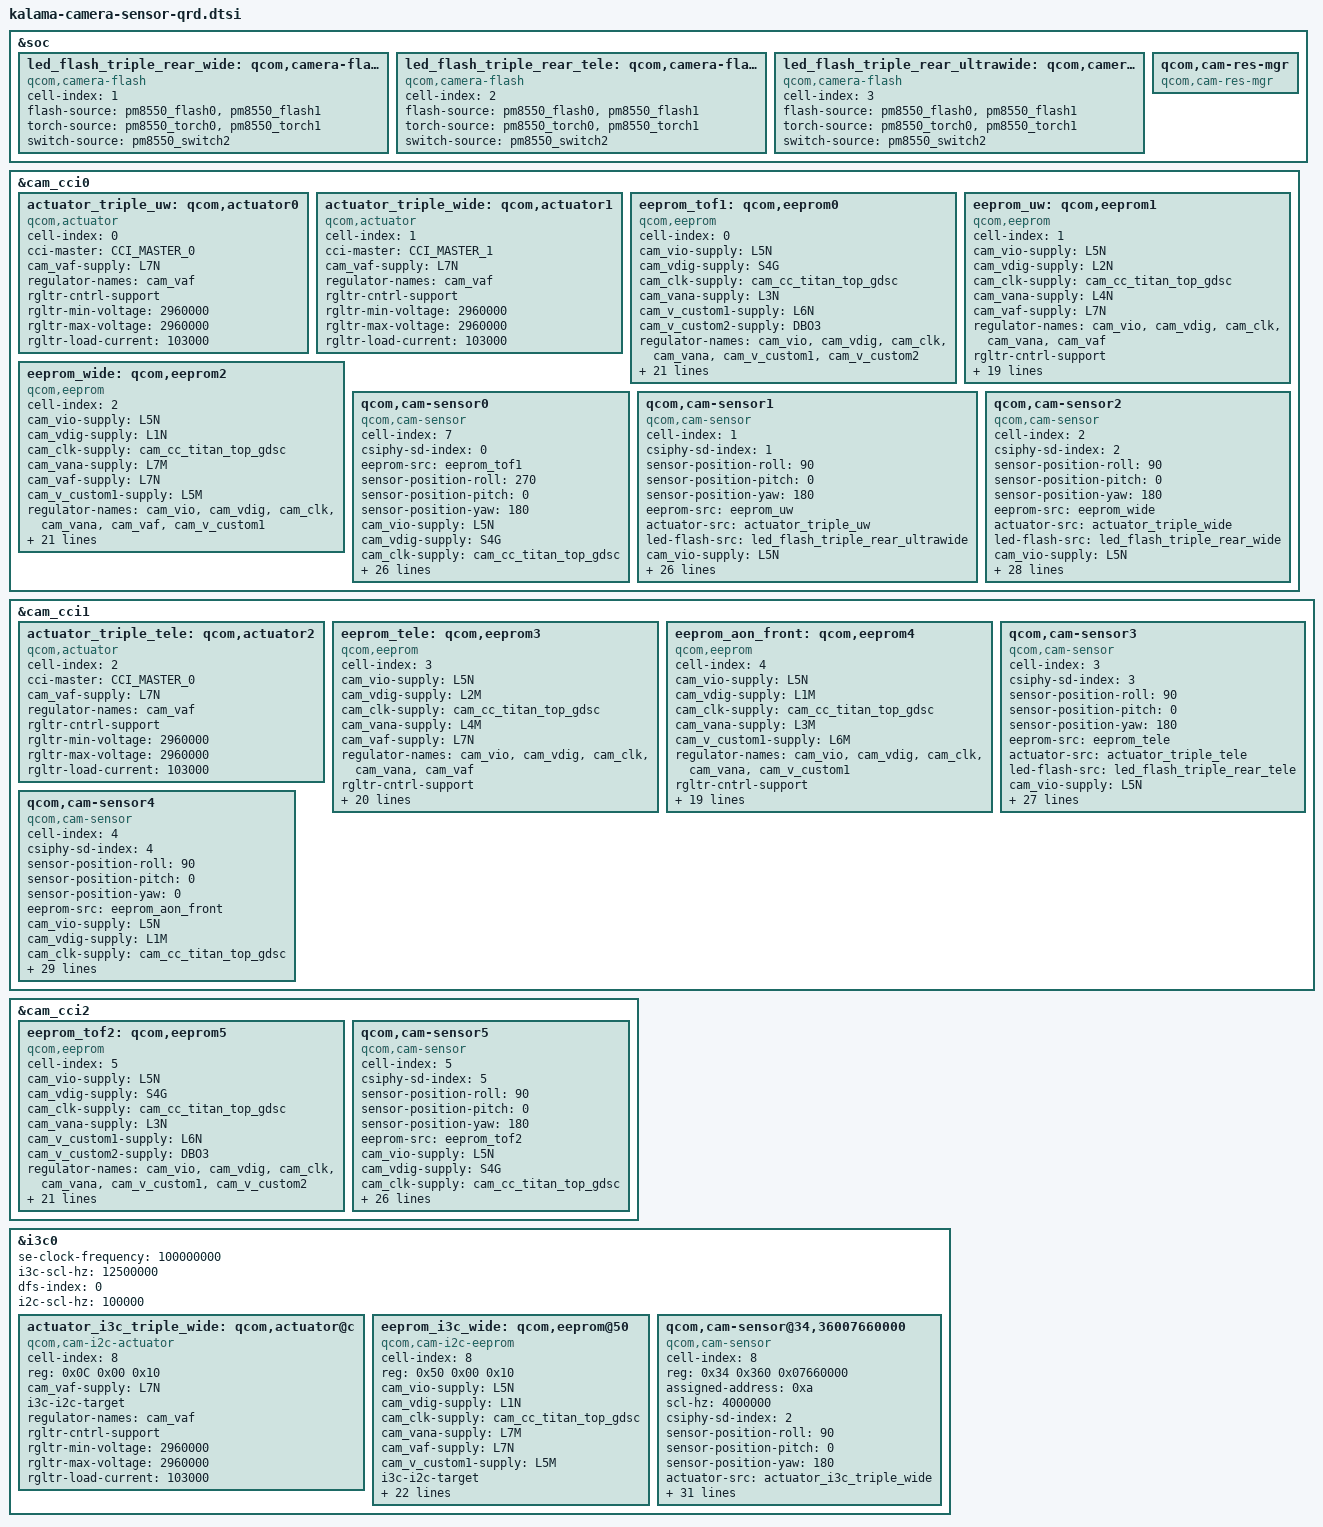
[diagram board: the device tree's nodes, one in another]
#include <dt-bindings/msm-camera.h>

&soc {
	led_flash_triple_rear_wide: qcom,camera-flash1 {
		cell-index = <1>;
		compatible = "qcom,camera-flash";
		flash-source = <&pm8550_flash0 &pm8550_flash1>;
		torch-source = <&pm8550_torch0 &pm8550_torch1>;
		switch-source = <&pm8550_switch2>;
		status = "ok";
	};

	led_flash_triple_rear_tele: qcom,camera-flash2 {
		cell-index = <2>;
		compatible = "qcom,camera-flash";
		flash-source = <&pm8550_flash0 &pm8550_flash1>;
		torch-source = <&pm8550_torch0 &pm8550_torch1>;
		switch-source = <&pm8550_switch2>;
		status = "ok";
	};

	led_flash_triple_rear_ultrawide: qcom,camera-flash3 {
		cell-index = <3>;
		compatible = "qcom,camera-flash";
		flash-source = <&pm8550_flash0 &pm8550_flash1>;
		torch-source = <&pm8550_torch0 &pm8550_torch1>;
		switch-source = <&pm8550_switch2>;
		status = "ok";
	};

	qcom,cam-res-mgr {
		compatible = "qcom,cam-res-mgr";
		status = "ok";
	};
};

&cam_cci0 {
	actuator_triple_uw: qcom,actuator0 {
		cell-index = <0>;
		compatible = "qcom,actuator";
		cci-master = <CCI_MASTER_0>;
		cam_vaf-supply = <&L7N>;
		regulator-names = "cam_vaf";
		rgltr-cntrl-support;
		rgltr-min-voltage = <2960000>;
		rgltr-max-voltage = <2960000>;
		rgltr-load-current = <103000>;
		status = "ok";
	};

	actuator_triple_wide: qcom,actuator1 {
		cell-index = <1>;
		compatible = "qcom,actuator";
		cci-master = <CCI_MASTER_1>;
		cam_vaf-supply = <&L7N>;
		regulator-names = "cam_vaf";
		rgltr-cntrl-support;
		rgltr-min-voltage = <2960000>;
		rgltr-max-voltage = <2960000>;
		rgltr-load-current = <103000>;
		status = "ok";
	};

	eeprom_tof1: qcom,eeprom0 {
		cell-index = <0>;
		compatible = "qcom,eeprom";
		cam_vio-supply = <&L5N>;
		cam_vdig-supply = <&S4G>;
		cam_clk-supply = <&cam_cc_titan_top_gdsc>;
		cam_vana-supply = <&L3N>;
		cam_v_custom1-supply = <&L6N>;
		cam_v_custom2-supply = <&DBO3>;
		regulator-names = "cam_vio", "cam_vdig",
			"cam_clk", "cam_vana", "cam_v_custom1", "cam_v_custom2";
		rgltr-cntrl-support;
		rgltr-min-voltage = <1800000 1200000 0 2800000 3304000 3600000>;
		rgltr-max-voltage = <1800000 1352000 0 2800000 3304000 3600000>;
		rgltr-load-current = <155000 680000 0 50000 30000 2500000>;
		gpio-no-mux = <0>;
		pinctrl-names = "cam_default", "cam_suspend";
		pinctrl-0 = <&cam_sensor_mclk0_active
			&cam_sensor_active_rst0>;
		pinctrl-1 = <&cam_sensor_mclk0_suspend
			&cam_sensor_suspend_rst0>;
		gpios = <&tlmm 100 0>,
			<&tlmm 116 0>;
		gpio-reset = <1>;
		gpio-req-tbl-num = <0 1>;
		gpio-req-tbl-flags = <1 0>;
		gpio-req-tbl-label = "CAMIF_MCLK0",
					"CAM_RESET0";
		cci-master = <CCI_MASTER_0>;
		clocks = <&camcc CAM_CC_MCLK0_CLK>;
		clock-names = "cam_clk";
		clock-cntl-level = "nominal";
		clock-rates = <24000000>;
		status = "ok";
	};

	eeprom_uw: qcom,eeprom1 {
		cell-index = <1>;
		compatible = "qcom,eeprom";
		cam_vio-supply = <&L5N>;
		cam_vdig-supply = <&L2N>;
		cam_clk-supply = <&cam_cc_titan_top_gdsc>;
		cam_vana-supply = <&L4N>;
		cam_vaf-supply = <&L7N>;
		regulator-names = "cam_vio", "cam_vdig", "cam_clk",
			"cam_vana","cam_vaf";
		rgltr-cntrl-support;
		rgltr-min-voltage = <1800000 1104000 0 2800000  2960000>;
		rgltr-max-voltage = <1800000 1104000 0 2800000  2960000>;
		rgltr-load-current = <3000 644000 0 95000  103000>;
		gpio-no-mux = <0>;
		pinctrl-names = "cam_default", "cam_suspend";
		pinctrl-0 = <&cam_sensor_mclk1_active
				 &cam_sensor_active_rst1>;
		pinctrl-1 = <&cam_sensor_mclk1_suspend
				 &cam_sensor_suspend_rst1>;
		gpios = <&tlmm 101 0>,
			<&tlmm 117 0>;
		gpio-reset = <1>;
		gpio-req-tbl-num = <0 1>;
		gpio-req-tbl-flags = <1 0>;
		gpio-req-tbl-label = "CAMIF_MCLK1",
					"CAM_RESET1";
		cci-master = <CCI_MASTER_0>;
		clocks = <&camcc CAM_CC_MCLK1_CLK>;
		clock-names = "cam_clk";
		clock-cntl-level = "nominal";
		clock-rates = <24000000>;
		status = "ok";
	};

	eeprom_wide: qcom,eeprom2 {
		cell-index = <2>;
		compatible = "qcom,eeprom";
		cam_vio-supply = <&L5N>;
		cam_vdig-supply = <&L1N>;
		cam_clk-supply = <&cam_cc_titan_top_gdsc>;
		cam_vana-supply = <&L7M>;
		cam_vaf-supply = <&L7N>;
		cam_v_custom1-supply = <&L5M>;
		regulator-names = "cam_vio", "cam_vdig", "cam_clk", "cam_vana",
			"cam_vaf", "cam_v_custom1";
		rgltr-cntrl-support;
		rgltr-min-voltage = <1800000 1104000 0 2800000 2960000 1800000>;
		rgltr-max-voltage = <1800000 1104000 0 2800000 2960000 1800000>;
		rgltr-load-current = <3500 913200 0 91300 103000 63100>;
		gpio-no-mux = <0>;
		pinctrl-names = "cam_default", "cam_suspend";
		pinctrl-0 = <&cam_sensor_mclk2_active
				&cam_sensor_active_rst2>;
		pinctrl-1 = <&cam_sensor_mclk2_suspend
				&cam_sensor_suspend_rst2>;
		gpios = <&tlmm 102 0>,
			<&tlmm 118 0>;
		gpio-reset = <1>;
		gpio-req-tbl-num = <0 1>;
		gpio-req-tbl-flags = <1 0>;
		gpio-req-tbl-label = "CAMIF_MCLK2",
					"CAM_RESET2";
		cci-master = <CCI_MASTER_1>;
		clocks = <&camcc CAM_CC_MCLK2_CLK>;
		clock-names = "cam_clk";
		clock-cntl-level = "nominal";
		clock-rates = <24000000>;
		status = "ok";
	};

	qcom,cam-sensor0 {
		cell-index = <7>;
		compatible = "qcom,cam-sensor";
		csiphy-sd-index = <0>;
		eeprom-src = <&eeprom_tof1>;
		sensor-position-roll = <270>;
		sensor-position-pitch = <0>;
		sensor-position-yaw = <180>;
		cam_vio-supply = <&L5N>;
		cam_vdig-supply = <&S4G>;
		cam_clk-supply = <&cam_cc_titan_top_gdsc>;
		cam_vana-supply = <&L3N>;
		cam_v_custom1-supply = <&L6N>;
		cam_v_custom2-supply = <&DBO3>;
		regulator-names = "cam_vio", "cam_vdig",
			"cam_clk", "cam_vana", "cam_v_custom1", "cam_v_custom2";
		rgltr-cntrl-support;
		rgltr-min-voltage = <1800000 1200000 0 2800000 3304000 3600000>;
		rgltr-max-voltage = <1800000 1352000 0 2800000 3304000 3600000>;
		rgltr-load-current = <155000 680000 0 50000 30000 2500000>;
		gpio-no-mux = <0>;
		pinctrl-names = "cam_default", "cam_suspend";
		pinctrl-0 = <&cam_sensor_mclk0_active
			&cam_sensor_active_rst0>;
		pinctrl-1 = <&cam_sensor_mclk0_suspend
			&cam_sensor_suspend_rst0>;
		gpios = <&tlmm 100 0>,
			<&tlmm 116 0>;
		gpio-reset = <1>;
		gpio-req-tbl-num = <0 1>;
		gpio-req-tbl-flags = <1 0>;
		gpio-req-tbl-label = "CAMIF_MCLK0",
					"CAM_RESET0";
		cci-master = <0>;
		clocks = <&camcc CAM_CC_MCLK0_CLK>;
		clock-names = "cam_clk";
		clock-cntl-level = "nominal";
		clock-rates = <24000000>;
		status = "ok";
	};

	qcom,cam-sensor1 {
		cell-index = <1>;
		compatible = "qcom,cam-sensor";
		csiphy-sd-index = <1>;
		sensor-position-roll = <90>;
		sensor-position-pitch = <0>;
		sensor-position-yaw = <180>;
		eeprom-src = <&eeprom_uw>;
		actuator-src = <&actuator_triple_uw>;
		led-flash-src = <&led_flash_triple_rear_ultrawide>;
		cam_vio-supply = <&L5N>;
		cam_vdig-supply = <&L2N>;
		cam_clk-supply = <&cam_cc_titan_top_gdsc>;
		cam_vana-supply = <&L4N>;
		cam_vaf-supply = <&L7N>;
		regulator-names = "cam_vio", "cam_vdig", "cam_clk",
			"cam_vana","cam_vaf";
		rgltr-cntrl-support;
		rgltr-min-voltage = <1800000 1104000 0 2800000  2960000>;
		rgltr-max-voltage = <1800000 1104000 0 2800000  2960000>;
		rgltr-load-current = <3000 644000 0 95000  103000>;
		gpio-no-mux = <0>;
		pinctrl-names = "cam_default", "cam_suspend";
		pinctrl-0 = <&cam_sensor_mclk1_active
				 &cam_sensor_active_rst1>;
		pinctrl-1 = <&cam_sensor_mclk1_suspend
				 &cam_sensor_suspend_rst1>;
		gpios = <&tlmm 101 0>,
			<&tlmm 117 0>;
		gpio-reset = <1>;
		gpio-req-tbl-num = <0 1>;
		gpio-req-tbl-flags = <1 0>;
		gpio-req-tbl-label = "CAMIF_MCLK1",
					"CAM_RESET1";
		cci-master = <CCI_MASTER_0>;
		clocks = <&camcc CAM_CC_MCLK1_CLK>;
		clock-names = "cam_clk";
		clock-cntl-level = "nominal";
		clock-rates = <24000000>;
		status = "ok";
	};

	qcom,cam-sensor2 {
		cell-index = <2>;
		compatible = "qcom,cam-sensor";
		csiphy-sd-index = <2>;
		sensor-position-roll = <90>;
		sensor-position-pitch = <0>;
		sensor-position-yaw = <180>;
		eeprom-src = <&eeprom_wide>;
		actuator-src = <&actuator_triple_wide>;
		led-flash-src = <&led_flash_triple_rear_wide>;
		cam_vio-supply = <&L5N>;
		cam_vdig-supply = <&L1N>;
		cam_clk-supply = <&cam_cc_titan_top_gdsc>;
		cam_vana-supply = <&L7M>;
		cam_vaf-supply = <&L7N>;
		cam_v_custom1-supply = <&L5M>;
		regulator-names = "cam_vio", "cam_vdig", "cam_clk", "cam_vana",
			"cam_vaf", "cam_v_custom1";
		rgltr-cntrl-support;
		rgltr-min-voltage = <1800000 1104000 0 2800000 2960000 1800000>;
		rgltr-max-voltage = <1800000 1104000 0 2800000 2960000 1800000>;
		rgltr-load-current = <3500 913200 0 91300 103000 63100>;
		gpio-no-mux = <0>;
		pinctrl-names = "cam_default", "cam_suspend";
		pinctrl-0 = <&cam_sensor_mclk2_active
				 &cam_sensor_active_rst2>;
		pinctrl-1 = <&cam_sensor_mclk2_suspend
				 &cam_sensor_suspend_rst2>;
		gpios = <&tlmm 102 0>,
			<&tlmm 118 0>;
		gpio-reset = <1>;
		gpio-req-tbl-num = <0 1>;
		gpio-req-tbl-flags = <1 0>;
		gpio-req-tbl-label = "CAMIF_MCLK2",
					"CAM_RESET2";
		cci-master = <CCI_MASTER_1>;
		clocks = <&camcc CAM_CC_MCLK2_CLK>;
		clock-names = "cam_clk";
		clock-cntl-level = "nominal";
		clock-rates = <24000000>;
		status = "ok";
	};

};

&cam_cci1 {
	actuator_triple_tele: qcom,actuator2{
		cell-index = <2>;
		compatible = "qcom,actuator";
		cci-master = <CCI_MASTER_0>;
		cam_vaf-supply = <&L7N>;
		regulator-names = "cam_vaf";
		rgltr-cntrl-support;
		rgltr-min-voltage = <2960000>;
		rgltr-max-voltage = <2960000>;
		rgltr-load-current = <103000>;
		status = "ok";
	};

	eeprom_tele: qcom,eeprom3 {
		cell-index = <3>;
		compatible = "qcom,eeprom";
		cam_vio-supply = <&L5N>;
		cam_vdig-supply = <&L2M>;
		cam_clk-supply = <&cam_cc_titan_top_gdsc>;
		cam_vana-supply = <&L4M>;
		cam_vaf-supply = <&L7N>;
		regulator-names = "cam_vio", "cam_vdig", "cam_clk",
			"cam_vana", "cam_vaf";
		rgltr-cntrl-support;
		rgltr-min-voltage = <1800000 1056000 0 2800000 2960000>;
		rgltr-max-voltage = <1800000 1056000 0 2800000 2960000>;
		rgltr-load-current = <10000 140400 0 52000 103000>;
		gpio-no-mux = <0>;
		pinctrl-names = "cam_default", "cam_suspend";
		pinctrl-0 = <&cam_sensor_mclk3_active
				 &cam_sensor_active_rst3>;
		pinctrl-1 = <&cam_sensor_mclk3_suspend
				 &cam_sensor_suspend_rst3>;
		gpios = <&tlmm 103 0>,
			<&tlmm 119 0>;
		gpio-reset = <1>;
		gpio-req-tbl-num = <0 1>;
		gpio-req-tbl-flags = <1 0>;
		gpio-req-tbl-label = "CAMIF_MCLK3",
					"CAM_RESET3";
		cci-master = <CCI_MASTER_0>;
		clocks = <&camcc CAM_CC_MCLK3_CLK>;
		clock-names = "cam_clk";
		clock-cntl-level = "nominal";
		clock-rates = <24000000>;
		status = "ok";
	};

	eeprom_aon_front: qcom,eeprom4 {
		cell-index = <4>;
		compatible = "qcom,eeprom";
		cam_vio-supply = <&L5N>;
		cam_vdig-supply = <&L1M>;
		cam_clk-supply = <&cam_cc_titan_top_gdsc>;
		cam_vana-supply = <&L3M>;
		cam_v_custom1-supply = <&L6M>;
		regulator-names = "cam_vio", "cam_vdig","cam_clk", "cam_vana",
			"cam_v_custom1";
		rgltr-cntrl-support;
		rgltr-min-voltage = <1800000 1056000 0 2800000 1800000>;
		rgltr-max-voltage = <1800000 1056000 0 2800000 1800000>;
		rgltr-load-current = <6000 454000 0  77900 29400>;
		gpio-no-mux = <0>;
		pinctrl-names = "cam_default", "cam_suspend";
		pinctrl-0 = <&cam_sensor_mclk4_active
				 &cam_sensor_active_rst4>;
		pinctrl-1 = <&cam_sensor_mclk4_suspend
				 &cam_sensor_suspend_rst4>;
		gpios = <&tlmm 104 0>,
			<&tlmm 120 0>;
		gpio-reset = <1>;
		gpio-req-tbl-num = <0 1>;
		gpio-req-tbl-flags = <1 0>;
		gpio-req-tbl-label = "CAMIF_MCLK4",
					"CAM_RESET4";
		cci-master = <CCI_MASTER_1>;
		clocks = <&camcc CAM_CC_MCLK4_CLK>;
		clock-names = "cam_clk";
		clock-cntl-level = "nominal";
		clock-rates = <24000000>;
		status = "ok";
	};

	qcom,cam-sensor3 {
		cell-index = <3>;
		compatible = "qcom,cam-sensor";
		csiphy-sd-index = <3>;
		sensor-position-roll = <90>;
		sensor-position-pitch = <0>;
		sensor-position-yaw = <180>;
		eeprom-src = <&eeprom_tele>;
		actuator-src = <&actuator_triple_tele>;
		led-flash-src = <&led_flash_triple_rear_tele>;
		cam_vio-supply = <&L5N>;
		cam_vdig-supply = <&L2M>;
		cam_clk-supply = <&cam_cc_titan_top_gdsc>;
		cam_vana-supply = <&L4M>;
		cam_vaf-supply = <&L7N>;
		regulator-names = "cam_vio", "cam_vdig", "cam_clk",
			"cam_vana", "cam_vaf";
		rgltr-cntrl-support;
		rgltr-min-voltage = <1800000 1056000 0 2800000 2960000>;
		rgltr-max-voltage = <1800000 1056000 0 2800000 2960000>;
		rgltr-load-current = <10000 140400 0 52000 103000>;
		gpio-no-mux = <0>;
		pinctrl-names = "cam_default", "cam_suspend";
		pinctrl-0 = <&cam_sensor_mclk3_active
				 &cam_sensor_active_rst3>;
		pinctrl-1 = <&cam_sensor_mclk3_suspend
				 &cam_sensor_suspend_rst3>;
		gpios = <&tlmm 103 0>,
			<&tlmm 119 0>;
		gpio-reset = <1>;
		gpio-req-tbl-num = <0 1>;
		gpio-req-tbl-flags = <1 0>;
		gpio-req-tbl-label = "CAMIF_MCLK3",
					"CAM_RESET3";
		cci-master = <CCI_MASTER_0>;
		clocks = <&camcc CAM_CC_MCLK3_CLK>;
		clock-names = "cam_clk";
		clock-cntl-level = "nominal";
		clock-rates = <24000000>;
		status = "ok";
	};

	qcom,cam-sensor4 {
		cell-index = <4>;
		compatible = "qcom,cam-sensor";
		csiphy-sd-index = <4>;
		sensor-position-roll = <90>;
		sensor-position-pitch = <0>;
		sensor-position-yaw = <0>;
		eeprom-src = <&eeprom_aon_front>;
		cam_vio-supply = <&L5N>;
		cam_vdig-supply = <&L1M>;
		cam_clk-supply = <&cam_cc_titan_top_gdsc>;
		cam_vana-supply = <&L3M>;
		cam_v_custom1-supply = <&L6M>;
		regulator-names = "cam_vio", "cam_vdig","cam_clk", "cam_vana",
			"cam_v_custom1";
		rgltr-cntrl-support;
		aon-camera-id = <AON_CAM1>;
		rgltr-min-voltage = <1800000 1056000 0 2800000 1800000>;
		rgltr-max-voltage = <1800000 1056000 0 2800000 1800000>;
		rgltr-load-current = <6000 454000 0  77900 29400>;
		gpio-no-mux = <0>;
		pinctrl-names = "cam_default", "cam_suspend";
		pinctrl-0 = <&cam_sensor_mclk4_active
				 &cam_sensor_active_rst4
				 &cam_sensor_ponv_active>;
		pinctrl-1 = <&cam_sensor_mclk4_suspend
				 &cam_sensor_suspend_rst4
				 &cam_sensor_ponv_suspend>;
		gpios = <&tlmm 104 0>,
			<&tlmm 120 0>,
			<&tlmm 206 0>;
		gpio-reset = <1>;
		gpio-standby = <2>;
		gpio-req-tbl-num = <0 1 2>;
		gpio-req-tbl-flags = <1 0 0>;
		gpio-req-tbl-label = "CAMIF_MCLK4",
					"CAM_RESET4",
					"CAM_STANDBY";
		cci-master = <CCI_MASTER_1>;
		clocks = <&camcc CAM_CC_MCLK4_CLK>;
		clock-names = "cam_clk";
		clock-cntl-level = "nominal";
		clock-rates = <24000000>;
		status = "ok";
	};

};

&cam_cci2 {
	eeprom_tof2: qcom,eeprom5 {
		cell-index = <5>;
		compatible = "qcom,eeprom";
		cam_vio-supply = <&L5N>;
		cam_vdig-supply = <&S4G>;
		cam_clk-supply = <&cam_cc_titan_top_gdsc>;
		cam_vana-supply = <&L3N>;
		cam_v_custom1-supply = <&L6N>;
		cam_v_custom2-supply = <&DBO3>;
		regulator-names = "cam_vio", "cam_vdig", "cam_clk", "cam_vana", "cam_v_custom1",
			"cam_v_custom2";
		rgltr-cntrl-support;
		rgltr-min-voltage = <1800000 1200000 0 2800000 3304000 3600000>;
		rgltr-max-voltage = <1800000 1352000 0 2800000 3304000 3600000>;
		rgltr-load-current = <155000 680000 0 50000 30000 2500000>;
		gpio-no-mux = <0>;
		pinctrl-names = "cam_default", "cam_suspend";
		pinctrl-0 = <&cam_sensor_mclk5_active
			&cam_sensor_active_rst5>;
		pinctrl-1 = <&cam_sensor_mclk5_suspend
			&cam_sensor_suspend_rst5>;
		gpios = <&tlmm 105 0>,
			<&tlmm 69 0>;
		gpio-reset = <1>;
		gpio-req-tbl-num = <0 1>;
		gpio-req-tbl-flags = <1 0>;
		gpio-req-tbl-label = "CAMIF_MCLK5",
			"CAM_RESET5";
		cci-master = <CCI_MASTER_0>;
		clocks = <&camcc CAM_CC_MCLK5_CLK>;
		clock-names = "cam_clk";
		clock-cntl-level = "nominal";
		clock-rates = <24000000>;
		status = "ok";
	};

	qcom,cam-sensor5 {
		cell-index = <5>;
		compatible = "qcom,cam-sensor";
		csiphy-sd-index = <5>;
		sensor-position-roll = <90>;
		sensor-position-pitch = <0>;
		sensor-position-yaw = <180>;
		eeprom-src = <&eeprom_tof2>;
		cam_vio-supply = <&L5N>;
		cam_vdig-supply = <&S4G>;
		cam_clk-supply = <&cam_cc_titan_top_gdsc>;
		cam_vana-supply = <&L3N>;
		cam_v_custom1-supply = <&L6N>;
		cam_v_custom2-supply = <&DBO3>;
		regulator-names = "cam_vio", "cam_vdig", "cam_clk", "cam_vana", "cam_v_custom1",
			"cam_v_custom2";
		rgltr-cntrl-support;
		rgltr-min-voltage = <1800000 1200000 0 2800000 3304000 3600000>;
		rgltr-max-voltage = <1800000 1352000 0 2800000 3304000 3600000>;
		rgltr-load-current = <155000 680000 0 50000 30000 2500000>;
		gpio-no-mux = <0>;
		pinctrl-names = "cam_default", "cam_suspend";
		pinctrl-0 = <&cam_sensor_mclk5_active
				 &cam_sensor_active_rst5>;
		pinctrl-1 = <&cam_sensor_mclk5_suspend
				 &cam_sensor_suspend_rst5>;
		gpios = <&tlmm 105 0>,
			<&tlmm 69 0>;
		gpio-reset = <1>;
		gpio-req-tbl-num = <0 1>;
		gpio-req-tbl-flags = <1 0>;
		gpio-req-tbl-label = "CAMIF_MCLK5",
					"CAM_RESET5";
		cci-master = <CCI_MASTER_0>;
		clocks = <&camcc CAM_CC_MCLK5_CLK>;
		clock-names = "cam_clk";
		clock-cntl-level = "nominal";
		clock-rates = <24000000>;
		status = "ok";
	};

};

&i3c0 {
	se-clock-frequency = <100000000>;
	i3c-scl-hz = <12500000>;
	dfs-index = <0>;
	i2c-scl-hz = <100000>;
	status = "ok";

	actuator_i3c_triple_wide: qcom,actuator@c {
		cell-index = <8>;
		compatible = "qcom,cam-i2c-actuator", "qcom,actuator";
		reg = <0x0C 0x00 0x10>;
		cam_vaf-supply = <&L7N>;
		i3c-i2c-target;
		regulator-names = "cam_vaf";
		rgltr-cntrl-support;
		rgltr-min-voltage = <2960000>;
		rgltr-max-voltage = <2960000>;
		rgltr-load-current = <103000>;
		status = "ok";
	};

	eeprom_i3c_wide: qcom,eeprom@50 {
		cell-index = <8>;
		reg = <0x50 0x00 0x10>;
		compatible = "qcom,cam-i2c-eeprom", "qcom,eeprom";
		cam_vio-supply = <&L5N>;
		cam_vdig-supply = <&L1N>;
		cam_clk-supply = <&cam_cc_titan_top_gdsc>;
		cam_vana-supply = <&L7M>;
		cam_vaf-supply = <&L7N>;
		cam_v_custom1-supply = <&L5M>;
		i3c-i2c-target;
		regulator-names = "cam_vio", "cam_vdig", "cam_clk", "cam_vana",
			"cam_vaf", "cam_v_custom1";
		rgltr-cntrl-support;
		rgltr-min-voltage = <1800000 1104000 0 2800000 2960000 1800000>;
		rgltr-max-voltage = <1800000 1104000 0 2800000 2960000 1800000>;
		rgltr-load-current = <3500 913200 0 91300 103000 63100>;
		gpio-no-mux = <0>;
		pinctrl-names = "cam_default", "cam_suspend";
		pinctrl-0 = <&cam_sensor_mclk2_active
				&cam_sensor_active_rst2>;
		pinctrl-1 = <&cam_sensor_mclk2_suspend
				&cam_sensor_suspend_rst2>;
		gpios = <&tlmm 102 0>,
			<&tlmm 118 0>;
		gpio-reset = <1>;
		gpio-req-tbl-num = <0 1>;
		gpio-req-tbl-flags = <1 0>;
		gpio-req-tbl-label = "CAMIF_MCLK2",
					"CAM_RESET2";
		clocks = <&camcc CAM_CC_MCLK2_CLK>;
		clock-names = "cam_clk";
		clock-cntl-level = "nominal";
		clock-rates = <24000000>;
		status = "ok";
	};

	qcom,cam-sensor@34,36007660000 {
		cell-index = <8>;
		reg = <0x34 0x360 0x07660000>;
		assigned-address = <0xa>;
		scl-hz = <4000000>;
		compatible = "qcom,cam-sensor";
		csiphy-sd-index = <2>;
		sensor-position-roll = <90>;
		sensor-position-pitch = <0>;
		sensor-position-yaw = <180>;
		actuator-src = <&actuator_i3c_triple_wide>;
		eeprom-src = <&eeprom_i3c_wide>;
		led-flash-src = <&led_flash_triple_rear_wide>;
		cam_vio-supply = <&L5N>;
		cam_vdig-supply = <&L1N>;
		cam_clk-supply = <&cam_cc_titan_top_gdsc>;
		cam_vana-supply = <&L7M>;
		cam_vaf-supply = <&L7N>;
		cam_v_custom1-supply = <&L5M>;
		i3c-target;
		regulator-names = "cam_vio", "cam_vdig", "cam_clk", "cam_vana",
			"cam_vaf", "cam_v_custom1";
		rgltr-cntrl-support;
		rgltr-min-voltage = <1800000 1104000 0 2800000 2960000 1800000>;
		rgltr-max-voltage = <1800000 1104000 0 2800000 2960000 1800000>;
		rgltr-load-current = <3500 913200 0 91300 103000 63100>;
		gpio-no-mux = <0>;
		pinctrl-names = "cam_default", "cam_suspend";
		pinctrl-0 = <&cam_sensor_mclk2_active
				 &cam_sensor_active_rst2>;
		pinctrl-1 = <&cam_sensor_mclk2_suspend
				 &cam_sensor_suspend_rst2>;
		gpios = <&tlmm 102 0>,
			<&tlmm 118 0>;
		gpio-reset = <1>;
		gpio-req-tbl-num = <0 1>;
		gpio-req-tbl-flags = <1 0>;
		gpio-req-tbl-label = "CAMIF_MCLK2",
					"CAM_RESET2";
		clocks = <&camcc CAM_CC_MCLK2_CLK>;
		clock-names = "cam_clk";
		clock-cntl-level = "nominal";
		clock-rates = <24000000>;
		status = "ok";
	};
};
